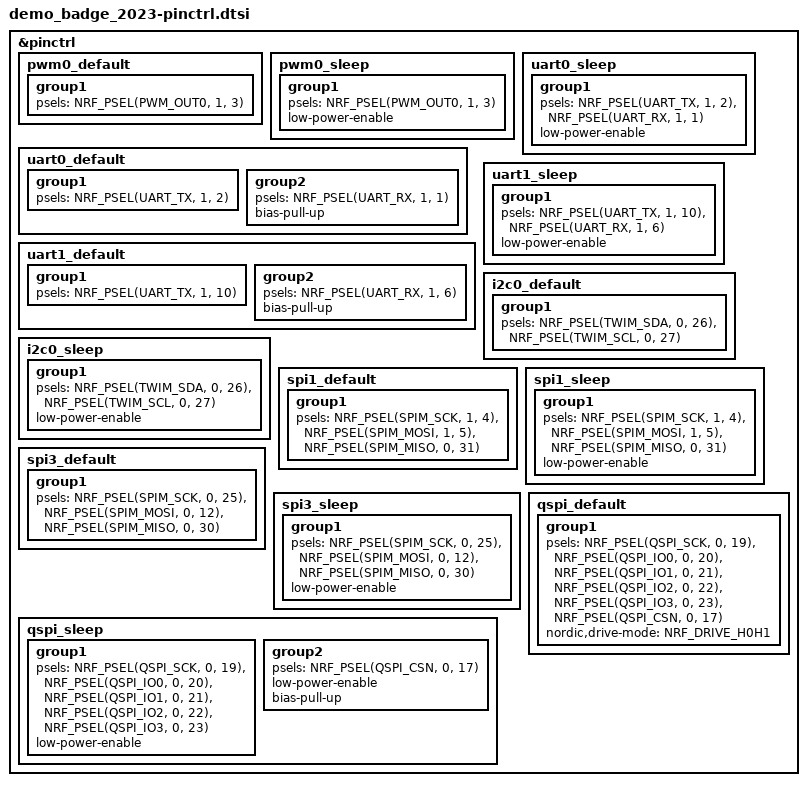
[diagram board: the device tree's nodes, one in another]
// Copyright Amazon.com, Inc. or its affiliates. All Rights Reserved.
// SPDX-License-Identifier: MIT-0

&pinctrl {
	pwm0_default: pwm0_default {
		group1 {
			psels = <NRF_PSEL(PWM_OUT0, 1, 3)>;
		};
	};

	pwm0_sleep: pwm0_sleep {
		group1 {
			psels = <NRF_PSEL(PWM_OUT0, 1, 3)>;
			low-power-enable;
		};
	};

	uart0_default: uart0_default {
		group1 {
			psels = <NRF_PSEL(UART_TX, 1, 2)>;
		};
		group2 {
			psels = <NRF_PSEL(UART_RX, 1, 1)>;
			bias-pull-up;
		};
	};

	uart0_sleep: uart0_sleep {
		group1 {
			psels = <NRF_PSEL(UART_TX, 1, 2)>,
					<NRF_PSEL(UART_RX, 1, 1)>;
			low-power-enable;
		};
	};

	uart1_default: uart1_default {
		group1 {
			psels = <NRF_PSEL(UART_TX, 1, 10)>;
		};
		group2 {
			psels = <NRF_PSEL(UART_RX, 1, 6)>;
			bias-pull-up;
		};
	};

	uart1_sleep: uart1_sleep {
		group1 {
			psels = <NRF_PSEL(UART_TX, 1, 10)>,
					<NRF_PSEL(UART_RX, 1, 6)>;
			low-power-enable;
		};
	};

	i2c0_default: i2c0_default {
		group1 {
			psels = <NRF_PSEL(TWIM_SDA, 0, 26)>,
					<NRF_PSEL(TWIM_SCL, 0, 27)>;
		};
	};

	i2c0_sleep: i2c0_sleep {
		group1 {
			psels = <NRF_PSEL(TWIM_SDA, 0, 26)>,
					<NRF_PSEL(TWIM_SCL, 0, 27)>;
			low-power-enable;
		};
	};

	spi1_default: spi1_default {
		group1 {
			psels = <NRF_PSEL(SPIM_SCK, 1, 4)>,
			        <NRF_PSEL(SPIM_MOSI, 1, 5)>,
			        <NRF_PSEL(SPIM_MISO, 0, 31)>;
		};
	};

	spi1_sleep: spi1_sleep {
		group1 {
			psels = <NRF_PSEL(SPIM_SCK, 1, 4)>,
			        <NRF_PSEL(SPIM_MOSI, 1, 5)>,
			        <NRF_PSEL(SPIM_MISO, 0, 31)>;
			low-power-enable;
		};
	};

	spi3_default: spi3_default {
		group1 {
			psels = <NRF_PSEL(SPIM_SCK, 0, 25)>, // not-connected in schematic
			<NRF_PSEL(SPIM_MOSI, 0, 12)>, // NEOPIXEL_DATA
			<NRF_PSEL(SPIM_MISO, 0, 30)>; // not-connected in schematic
		};
	};

	spi3_sleep: spi3_sleep {
		group1 {
			psels = <NRF_PSEL(SPIM_SCK, 0, 25)>, // not-connected in schematic
			<NRF_PSEL(SPIM_MOSI, 0, 12)>, // NEOPIXEL_DATA
			<NRF_PSEL(SPIM_MISO, 0, 30)>; // not-connected in schematic
			low-power-enable;
		};
	};

	qspi_default: qspi_default {
		group1 {
			psels = <NRF_PSEL(QSPI_SCK, 0, 19)>,
			        <NRF_PSEL(QSPI_IO0, 0, 20)>,
			        <NRF_PSEL(QSPI_IO1, 0, 21)>,
			        <NRF_PSEL(QSPI_IO2, 0, 22)>,
			        <NRF_PSEL(QSPI_IO3, 0, 23)>,
			        <NRF_PSEL(QSPI_CSN, 0, 17)>;
			nordic,drive-mode = <NRF_DRIVE_H0H1>;
		};
	};

	qspi_sleep: qspi_sleep {
		group1 {
			psels = <NRF_PSEL(QSPI_SCK, 0, 19)>,
			        <NRF_PSEL(QSPI_IO0, 0, 20)>,
			        <NRF_PSEL(QSPI_IO1, 0, 21)>,
			        <NRF_PSEL(QSPI_IO2, 0, 22)>,
			        <NRF_PSEL(QSPI_IO3, 0, 23)>;
			low-power-enable;
		};
		group2 {
			psels = <NRF_PSEL(QSPI_CSN, 0, 17)>;
			low-power-enable;
			bias-pull-up;
		};
	};
};
